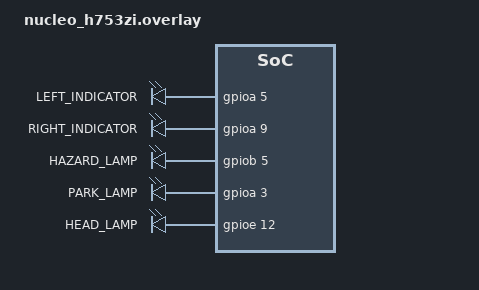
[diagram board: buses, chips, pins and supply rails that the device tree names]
/*
 * GPIO devicetree overlay for the body-control zonal lighting demo.
 *
 * Maps the five lamp output functions to GPIOB pins, matching the wiring
 * documented in nucleo_h753zi_pin_map.hpp and demo_walkthrough_hardware.md.
 *
 * Each node label is resolved at compile time by ZephyrGpioDriver via
 * GPIO_DT_SPEC_GET(DT_NODELABEL(<label>), gpios).
 *
 * Wiring: connect LED anode to the listed NUCLEO Morpho pin, cathode to
 * any GND pin, with a 330 Ω resistor in series.
 *   PB5 → Left Indicator
 *   PB1 → Right Indicator
 *   PB2 → Hazard Lamp
 *   PB3 → Park Lamp
 *   PB4 → Head Lamp
 */

/ {
    lamp_outputs {
        compatible = "gpio-leds";

        left_indicator: left_indicator {
            gpios = <&gpioa 5 GPIO_ACTIVE_HIGH>;
            label = "LEFT_INDICATOR";
        };

        right_indicator: right_indicator {
            gpios = <&gpioa 9 GPIO_ACTIVE_HIGH>;
            label = "RIGHT_INDICATOR";
        };

        hazard_lamp: hazard_lamp {
            gpios = <&gpiob 5 GPIO_ACTIVE_HIGH>;
            label = "HAZARD_LAMP";
        };

        park_lamp: park_lamp {
            gpios = <&gpioa 3 GPIO_ACTIVE_HIGH>;
            label = "PARK_LAMP";
        };

        head_lamp: head_lamp {
            gpios = <&gpioe 12 GPIO_ACTIVE_HIGH>;
            label = "HEAD_LAMP";
        };
    };
};
	
	&spi1 {
	   status = "disabled";
	};

	&adc1 {
	    status = "disabled";
	};

/*
 * Flash partition layout for MCUboot dual-slot OTA (Phase 13).
 *
 * STM32H753ZI: 2 MB internal flash, dual-bank (1 MB per bank).
 * Each bank has 8 sectors of 128 KB (erase-block-size = 128 KB,
 * write-block-size = 32 bytes).
 *
 * Addresses are offsets from the start of flash (0x08000000 CPU base).
 *
 * +------------------+------------+--------+---------------------------+
 * | Partition        | Offset     | Size   | Role                      |
 * +------------------+------------+--------+---------------------------+
 * | boot_partition   | 0x00000000 | 128 KB | MCUboot bootloader        |
 * | storage_partition| 0x00020000 | 128 KB | NVS / settings (reserved) |
 * | slot0_partition  | 0x00040000 | 768 KB | Primary image (bank 1)    |
 * | slot1_partition  | 0x00100000 | 768 KB | Secondary/OTA image       |
 * | scratch_partition| 0x001C0000 | 256 KB | Unused (swap-using-move)  |
 * +------------------+------------+--------+---------------------------+
 * Total: 2 MB exactly.
 *
 * Slot sizes (768 KB) cover current flash usage (113 KB) with room for
 * growth. boot_partition fits the MCUboot bootloader (~60 KB typical).
 * scratch_partition is present in DTS but unused with swap-using-move mode.
 *
 * The stock nucleo_h753zi.dts defines slot0 at @40000 (256 KB), slot1 at
 * @80000 (256 KB), and scratch at @c0000 (128 KB).  These are deleted below
 * before redefining them at the larger sizes required for the real application.
 * boot_partition (@0) and storage_partition (@20000) are kept as-is.
 */

/* Step 1: remove the undersized stock partitions to avoid label conflicts. */
&flash0 {
    partitions {
        /delete-node/ partition@40000;
        /delete-node/ partition@80000;
        /delete-node/ partition@c0000;
    };
};

/* Step 2: add the 768 KB slots and 256 KB scratch at their correct offsets. */
&flash0 {
    partitions {
        slot0_partition: partition@40000 {
            label = "image-0";
            reg = <0x00040000 DT_SIZE_K(768)>;
        };

        slot1_partition: partition@100000 {
            label = "image-1";
            reg = <0x00100000 DT_SIZE_K(768)>;
        };

        scratch_partition: partition@1C0000 {
            label = "image-scratch";
            reg = <0x001C0000 DT_SIZE_K(256)>;
        };
    };
};
